# R7FA6M4AF register map
Vendor: Renesas Electronics Corporation; Series: RA6; File version: 1.30.00
CPU: CM33 r0p4, little endian, MPU, FPU, VTOR, 4 interrupt priority bits, 96 interrupts
Registers are 8-bit, read-write, reset 0x0 unless marked. A register's access mark holds for its fields unless they carry their own. Offsets are from the block's base; [hi:lo] are bit positions; 'fields as' and 'values as' point back to an identical list.

## POEG — Port Output Enable Module for GPT
Base 0x4008A000
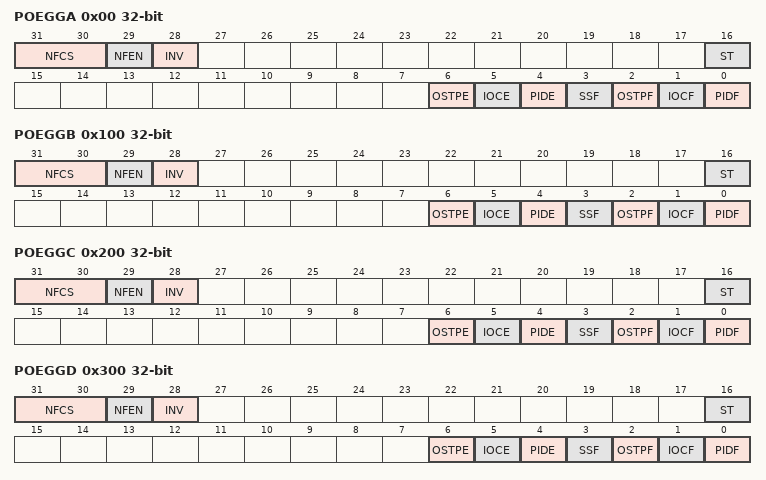
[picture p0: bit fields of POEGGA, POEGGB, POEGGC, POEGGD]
0x00 POEGGA 32-bit — POEG Group A Setting Register
  [31:30] NFCS — Noise Filter Clock Select
  [29] NFEN — Noise Filter Enable
  [28] INV — GTETRGn Input Reverse
  [16] ST ro — GTETRGn Input Status Flag
  [6] OSTPE — Oscillation Stop Detection Enable
  [5] IOCE — Enable for GPT Output,Disable Request
  [4] PIDE — Port Input Detection Enable
  [3] SSF — Software Stop Flag
  [2] OSTPF — Oscillation Stop Detection Flag
  [1] IOCF — Detection Flag for GPT Output,Disable Request
  [0] PIDF — Port Input Detection Flag
0x100 POEGGB 32-bit — POEG Group B Setting Register
  fields as POEGGA
0x200 POEGGC 32-bit — POEG Group C Setting Register
  fields as POEGGA
0x300 POEGGD 32-bit — POEG Group D Setting Register
  fields as POEGGA

## SSIE0 — Serial Sound Interface Enhanced (SSIE)
Base 0x4009D000
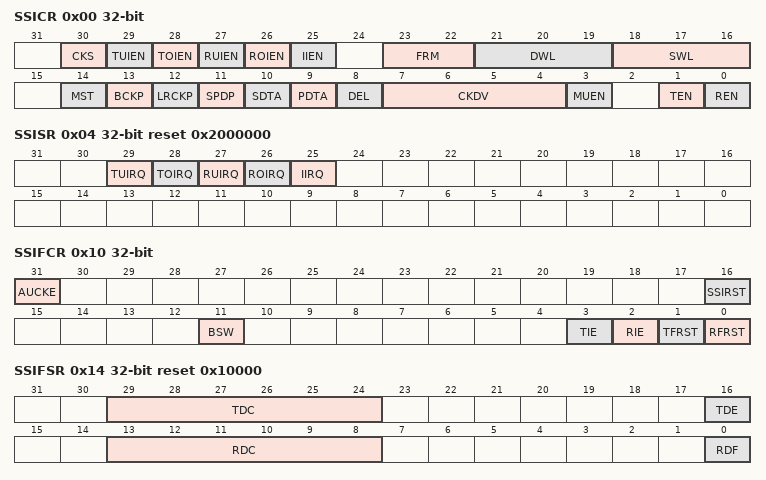
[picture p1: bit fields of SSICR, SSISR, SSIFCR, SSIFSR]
0x00 SSICR 32-bit — Control Register
  [30] CKS — Selects an Audio Clock for Master,mode Communication
  [29] TUIEN — Transmit Underflow Interrupt Output Enable
  [28] TOIEN — Transmit Overflow Interrupt Output Enable
  [27] RUIEN — Receive Underflow Interrupt Output Enable
  [26] ROIEN — Receive Overflow Interrupt Output Enable
  [25] IIEN — Idle Mode Interrupt Output Enable
  [23:22] FRM — Selects Frame Word Number
  [21:19] DWL — Selects Data Word Length
  [18:16] SWL — Selects System Word Length
  [14] MST — Master Enable
  [13] BCKP — Selects Bit Clock Polarity
  [12] LRCKP — Selects the Initial Value and Polarity of LR Clock/Frame Synchronization Signal
  [11] SPDP — Selects Serial Padding Polarity
  [10] SDTA — Selects Serial Data Alignment
  [9] PDTA — Selects Placement Data Alignment
  [8] DEL — Selects Serial Data Delay
  [7:4] CKDV — Selects Bit Clock Division Ratio
  [3] MUEN — Mute Enable
  [1] TEN — Transmission Enable
  [0] REN — Reception Enable
0x04 SSISR 32-bit reset 0x2000000 — Status Register
  [29] TUIRQ — Transmit Underflow Error Status flag
  [28] TOIRQ — Transmit Overflow Error Status Flag
  [27] RUIRQ — Receive Underflow Error Status Flag
  [26] ROIRQ — Receive Overflow Error Status Flag
  [25] IIRQ ro — Idle Mode Status Flag
0x10 SSIFCR 32-bit — FIFO Control Register
  [31] AUCKE — AUDIO_MCK Enable in Master,mode Communication
  [16] SSIRST — Software Reset
  [11] BSW — Byte Swap Enable
  [3] TIE — Transmit Data Empty Interrupt Output Enable
  [2] RIE — Receive Data Full Interrupt Output Enable
  [1] TFRST — Transmit FIFO Data Register Reset
  [0] RFRST — Receive FIFO Data Register Reset
0x14 SSIFSR 32-bit reset 0x10000 — FIFO Status Register
  [29:24] TDC ro — Transmit Data Count
  [16] TDE — Transmit Data Empty Flag
  [13:8] RDC ro — Receive Data Count
  [0] RDF — Receive Data Full Flag
0x18 SSIFTDR 32-bit wo — Transmit FIFO Data Register
  [31:0] SSIFTDR — Transmit FIFO Data
0x1C SSIFRDR 32-bit ro — Receive FIFO Data Register
  [31:0] SSIFRDR — Receive FIFO Data
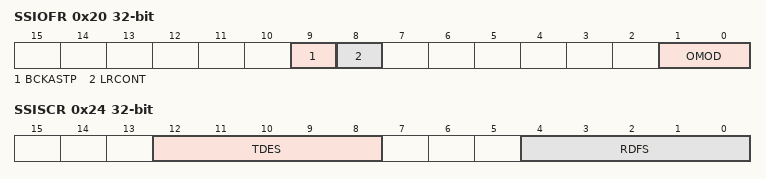
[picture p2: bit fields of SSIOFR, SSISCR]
0x20 SSIOFR 32-bit — Audio Format Register
  [9] BCKASTP — Whether to Enable Stopping BCK Output When SSIE is in Idle Status
  [8] LRCONT — Whether to Enable LRCK/FS Continuation
  [1:0] OMOD — Audio Format Select
0x24 SSISCR 32-bit — Status Control Register
  [12:8] TDES — TDE Setting Condition Select
  [4:0] RDFS — RDF Setting Condition Select

## IIC0WU — Inter,Integrated Circuit 0 Wake,up Unit
Base 0x4009F014
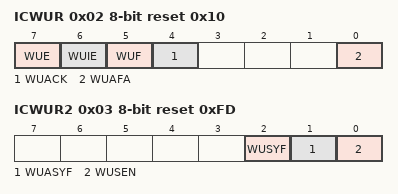
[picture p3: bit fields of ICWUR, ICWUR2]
0x02 ICWUR reset 0x10 — I2C Bus Wakeup Unit Register
  [7] WUE — Wakeup Function Enable
  [6] WUIE — Wakeup Interrupt Request Enable
  [5] WUF — Wakeup Event Occurrence Flag
  [4] WUACK — ACK Bit for Wakeup Mode
  [0] WUAFA — Wakeup Analog Filter Additional Selection
0x03 ICWUR2 reset 0xFD — I2C Bus Wakeup Unit Register 2
  [2] WUSYF ro — Wakeup Function Synchronous Operation Status Flag
  [1] WUASYF ro — Wakeup Function Asynchronous Operation Status Flag
  [0] WUSEN — Wakeup Function Synchronous Enable
